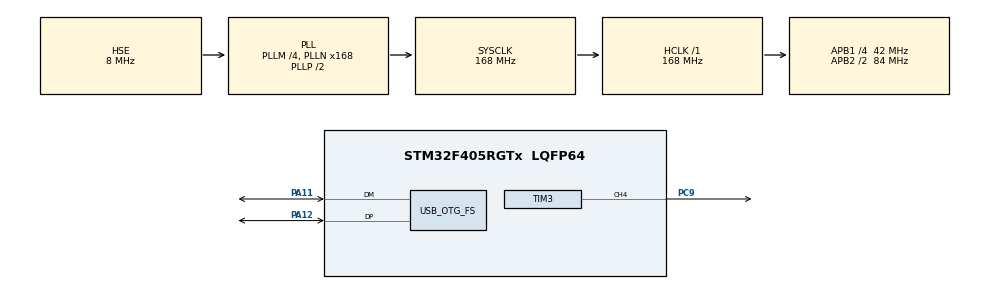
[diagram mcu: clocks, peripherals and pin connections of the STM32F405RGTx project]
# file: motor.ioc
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Mcu.Family=STM32F4
Mcu.Name=STM32F405RGTx
Mcu.Package=LQFP64
NVIC.OTG_FS_IRQn=true\:0\:0\:false\:false\:true\:false\:true\:true
NVIC.PriorityGroup=NVIC_PRIORITYGROUP_4
PA11.Mode=Device_Only
PA11.Signal=USB_OTG_FS_DM
PA12.Mode=Device_Only
PA12.Signal=USB_OTG_FS_DP
PA13.Mode=Serial_Wire
PA13.Signal=SYS_JTMS-SWDIO
PA14.Mode=Serial_Wire
PA14.Signal=SYS_JTCK-SWCLK
PC9.Signal=S_TIM3_CH4
PH0-OSC_IN.Mode=HSE-External-Oscillator
PH0-OSC_IN.Signal=RCC_OSC_IN
PH1-OSC_OUT.Mode=HSE-External-Oscillator
PH1-OSC_OUT.Signal=RCC_OSC_OUT
ProjectManager.HeapSize=0x200
ProjectManager.StackSize=0x400
ProjectManager.TargetToolchain=STM32CubeIDE
RCC.48MHZClocksFreq_Value=48000000
RCC.AHBFreq_Value=168000000
RCC.APB1CLKDivider=RCC_HCLK_DIV4
RCC.APB1Freq_Value=42000000
RCC.APB1TimFreq_Value=84000000
RCC.APB2CLKDivider=RCC_HCLK_DIV2
RCC.APB2Freq_Value=84000000
RCC.APB2TimFreq_Value=168000000
RCC.CortexFreq_Value=168000000
RCC.HCLKFreq_Value=168000000
RCC.HSE_VALUE=8000000
RCC.HSI_VALUE=16000000
RCC.LSE_VALUE=32768
RCC.PLLM=4
RCC.PLLN=168
RCC.PLLQ=7
RCC.SYSCLKFreq_VALUE=168000000
RCC.SYSCLKSource=RCC_SYSCLKSOURCE_PLLCLK
RCC.VCOOutputFreq_Value=336000000
SH.S_TIM3_CH4.0=TIM3_CH4,PWM Generation4 CH4
TIM3.Channel-PWM\ Generation4\ CH4=TIM_CHANNEL_4
TIM3.Period=1000-1
TIM3.Prescaler=1680-1
USB_DEVICE.CLASS_NAME_FS=CDC
USB_DEVICE.VirtualMode-CDC_FS=Cdc
USB_DEVICE.VirtualModeFS=Cdc_FS
USB_OTG_FS.VirtualMode=Device_Only
VP_TIM3_VS_ClockSourceINT.Mode=Internal
VP_USB_DEVICE_VS_USB_DEVICE_CDC_FS.Mode=CDC_FS
board=custom

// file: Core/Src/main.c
/* USER CODE BEGIN Header */
/**
  ******************************************************************************
  * @file           : main.c
  * @brief          : Main program body
  ******************************************************************************
  * @attention
  *
  * Copyright (c) 2023 STMicroelectronics.
  * All rights reserved.
  *
  * This software is licensed under terms that can be found in the LICENSE file
  * in the root directory of this software component.
  * If no LICENSE file comes with this software, it is provided AS-IS.
  *
  ******************************************************************************
  */
/* USER CODE END Header */
#include "main.h"
#include "tim.h"
#include "usb_device.h"
#include "gpio.h"
#include "usbd_cdc_if.h"

void SystemClock_Config(void);

/* USER CODE BEGIN 0 */

//void USB_Disconnected()
//{
//    __HAL_RCC_USB_OTG_FS_FORCE_RESET();
//    HAL_Delay(200);
//    __HAL_RCC_USB_OTG_FS_RELEASE_RESET();
//    GPIO_InitTypeDef GPIO_Initure;
//    __HAL_RCC_GPIOA_CLK_ENABLE();
//
//    GPIO_Initure.Pin = GPIO_PIN_11 | GPIO_PIN_12;
//    GPIO_Initure.Mode = GPIO_MODE_OUTPUT_PP;
//    GPIO_Initure.Pull = GPIO_PULLDOWN;
//    GPIO_Initure.Speed = GPIO_SPEED_FREQ_HIGH;
//    HAL_GPIO_Init(GPIOA, &GPIO_Initure);
//
//    HAL_GPIO_WritePin(GPIOA, GPIO_PIN_11, GPIO_PIN_RESET);
//    HAL_GPIO_WritePin(GPIOA, GPIO_PIN_12, GPIO_PIN_RESET);
//    HAL_Delay(300);
//}
/* USER CODE END 0 */

int main(void)
{

  /* MCU Configuration--------------------------------------------------------*/

  /* Reset of all peripherals, Initializes the Flash interface and the Systick. */
  HAL_Init();

  /* Configure the system clock */
  SystemClock_Config();

  /* USER CODE BEGIN SysInit */
//    USB_Disconnected();
  /* USER CODE END SysInit */

  /* Initialize all configured peripherals */
  MX_GPIO_Init();
  MX_TIM3_Init();
  MX_USB_DEVICE_Init();
  /* USER CODE BEGIN 2 */
  HAL_TIM_PWM_Start(&htim3,TIM_CHANNEL_4);
  /* USER CODE END 2 */

  /* Infinite loop */
  /* USER CODE BEGIN WHILE */
  while (1)
  {
      __HAL_TIM_SetCompare(&htim3, TIM_CHANNEL_4, *p_TempBuf*4);
      HAL_Delay(1000);
    /* USER CODE END WHILE */

  }
}

void SystemClock_Config(void)
{
  RCC_OscInitTypeDef RCC_OscInitStruct = {0};
  RCC_ClkInitTypeDef RCC_ClkInitStruct = {0};

  /** Configure the main internal regulator output voltage
  */
  __HAL_RCC_PWR_CLK_ENABLE();
  __HAL_PWR_VOLTAGESCALING_CONFIG(PWR_REGULATOR_VOLTAGE_SCALE1);

  /** Initializes the RCC Oscillators according to the specified parameters
  * in the RCC_OscInitTypeDef structure.
  */
  RCC_OscInitStruct.OscillatorType = RCC_OSCILLATORTYPE_HSE;
  RCC_OscInitStruct.HSEState = RCC_HSE_ON;
  RCC_OscInitStruct.PLL.PLLState = RCC_PLL_ON;
  RCC_OscInitStruct.PLL.PLLSource = RCC_PLLSOURCE_HSE;
  RCC_OscInitStruct.PLL.PLLM = 4;
  RCC_OscInitStruct.PLL.PLLN = 168;
  RCC_OscInitStruct.PLL.PLLP = RCC_PLLP_DIV2;
  RCC_OscInitStruct.PLL.PLLQ = 7;
  if (HAL_RCC_OscConfig(&RCC_OscInitStruct) != HAL_OK)
  {
    Error_Handler();
  }

  /** Initializes the CPU, AHB and APB buses clocks
  */
  RCC_ClkInitStruct.ClockType = RCC_CLOCKTYPE_HCLK|RCC_CLOCKTYPE_SYSCLK
                              |RCC_CLOCKTYPE_PCLK1|RCC_CLOCKTYPE_PCLK2;
  RCC_ClkInitStruct.SYSCLKSource = RCC_SYSCLKSOURCE_PLLCLK;
  RCC_ClkInitStruct.AHBCLKDivider = RCC_SYSCLK_DIV1;
  RCC_ClkInitStruct.APB1CLKDivider = RCC_HCLK_DIV4;
  RCC_ClkInitStruct.APB2CLKDivider = RCC_HCLK_DIV2;

  if (HAL_RCC_ClockConfig(&RCC_ClkInitStruct, FLASH_LATENCY_5) != HAL_OK)
  {
    Error_Handler();
  }
}

void Error_Handler(void)
{
  __disable_irq();
  while (1)
  {
  }
}
